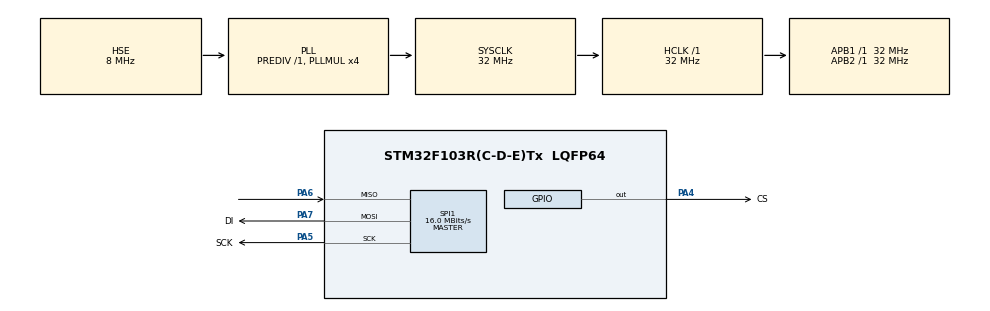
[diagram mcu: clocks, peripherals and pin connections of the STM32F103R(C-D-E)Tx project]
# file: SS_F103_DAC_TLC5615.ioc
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Mcu.Family=STM32F1
Mcu.Name=STM32F103R(C-D-E)Tx
Mcu.Package=LQFP64
NVIC.PriorityGroup=NVIC_PRIORITYGROUP_4
PA4.GPIO_Label=CS
PA4.GPIO_PuPd=GPIO_PULLUP
PA4.Signal=GPIO_Output
PA5.GPIO_Label=SCK
PA5.Mode=Full_Duplex_Master
PA5.Signal=SPI1_SCK
PA6.Mode=Full_Duplex_Master
PA6.Signal=SPI1_MISO
PA7.GPIO_Label=DI
PA7.Mode=Full_Duplex_Master
PA7.Signal=SPI1_MOSI
PD0-OSC_IN.Mode=HSE-External-Oscillator
PD0-OSC_IN.Signal=RCC_OSC_IN
PD1-OSC_OUT.Mode=HSE-External-Oscillator
PD1-OSC_OUT.Signal=RCC_OSC_OUT
ProjectManager.HeapSize=0x200
ProjectManager.StackSize=0x400
ProjectManager.TargetToolchain=MDK-ARM V5.27
RCC.AHBFreq_Value=32000000
RCC.APB1Freq_Value=32000000
RCC.APB1TimFreq_Value=32000000
RCC.APB2Freq_Value=32000000
RCC.APB2TimFreq_Value=32000000
RCC.HCLKFreq_Value=32000000
RCC.PLLMUL=RCC_PLL_MUL4
RCC.PLLSourceVirtual=RCC_PLLSOURCE_HSE
RCC.SYSCLKFreq_VALUE=32000000
RCC.SYSCLKSource=RCC_SYSCLKSOURCE_PLLCLK
RCC.USBFreq_Value=32000000
SPI1.BaudRatePrescaler=SPI_BAUDRATEPRESCALER_2
SPI1.CalculateBaudRate=16.0 MBits/s
SPI1.DataSize=SPI_DATASIZE_8BIT
SPI1.Direction=SPI_DIRECTION_2LINES
SPI1.Mode=SPI_MODE_MASTER
SPI1.VirtualType=VM_MASTER
VP_SYS_VS_ND.Mode=No_Debug
board=custom

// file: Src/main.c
/* USER CODE BEGIN Header */
/**
  ******************************************************************************
  * @file           : main.c
  * @brief          : Main program body
  ******************************************************************************
  * @attention
  *
  * <h2><center>&copy; Copyright (c) 2020 STMicroelectronics.
  * All rights reserved.</center></h2>
  *
  * This software component is licensed by ST under BSD 3-Clause license,
  * the "License"; You may not use this file except in compliance with the
  * License. You may obtain a copy of the License at:
  *                        opensource.org/licenses/BSD-3-Clause
  *
  ******************************************************************************
  */
/* USER CODE END Header */

#include "main.h"
#include "spi.h"
#include "gpio.h"

/* USER CODE BEGIN Includes */
#include "DAC_TLC5615.h"
#include "delay.h"
/* USER CODE END Includes */

void SystemClock_Config(void);

/* USER CODE BEGIN 0 */
FlagStatus SPI_I2S_GetFlagStatus(SPI_TypeDef* SPIx, uint16_t SPI_I2S_FLAG)
{
  FlagStatus bitstatus = RESET;
  /* Check the parameters */
  assert_param(IS_SPI_ALL_PERIPH(SPIx));
  assert_param(IS_SPI_I2S_GET_FLAG(SPI_I2S_FLAG));
  /* Check the status of the specified SPI/I2S flag */
  if ((SPIx->SR & SPI_I2S_FLAG) != (uint16_t)RESET)
  {
    /* SPI_I2S_FLAG is set */
    bitstatus = SET;
  }
  else
  {
    /* SPI_I2S_FLAG is reset */
    bitstatus = RESET;
  }
  /* Return the SPI_I2S_FLAG status */
  return  bitstatus;
}
/* USER CODE END 0 */

int main(void)
{

  /* MCU Configuration--------------------------------------------------------*/

  /* Reset of all peripherals, Initializes the Flash interface and the Systick. */
  HAL_Init();

  /* USER CODE BEGIN Init */
//typedef enum {RESET = 0, SET = !RESET} FlagStatus, ITStatus;
  /* USER CODE END Init */

  /* Configure the system clock */
  SystemClock_Config();

  /* USER CODE BEGIN SysInit */
	delay_init(32);
  /* USER CODE END SysInit */

  /* Initialize all configured peripherals */
  MX_GPIO_Init();
  MX_SPI1_Init();

  /* Infinite loop */
  /* USER CODE BEGIN WHILE */
  while (1)
  {
		//sin_wave();
		MF_Write_data_to_TLC5615(1023);
    /* USER CODE END WHILE */

  }
}

void SystemClock_Config(void)
{
  RCC_OscInitTypeDef RCC_OscInitStruct = {0};
  RCC_ClkInitTypeDef RCC_ClkInitStruct = {0};

  /** Initializes the CPU, AHB and APB busses clocks
  */
  RCC_OscInitStruct.OscillatorType = RCC_OSCILLATORTYPE_HSE;
  RCC_OscInitStruct.HSEState = RCC_HSE_ON;
  RCC_OscInitStruct.HSEPredivValue = RCC_HSE_PREDIV_DIV1;
  RCC_OscInitStruct.HSIState = RCC_HSI_ON;
  RCC_OscInitStruct.PLL.PLLState = RCC_PLL_ON;
  RCC_OscInitStruct.PLL.PLLSource = RCC_PLLSOURCE_HSE;
  RCC_OscInitStruct.PLL.PLLMUL = RCC_PLL_MUL4;
  if (HAL_RCC_OscConfig(&RCC_OscInitStruct) != HAL_OK)
  {
    Error_Handler();
  }
  /** Initializes the CPU, AHB and APB busses clocks
  */
  RCC_ClkInitStruct.ClockType = RCC_CLOCKTYPE_HCLK|RCC_CLOCKTYPE_SYSCLK
                              |RCC_CLOCKTYPE_PCLK1|RCC_CLOCKTYPE_PCLK2;
  RCC_ClkInitStruct.SYSCLKSource = RCC_SYSCLKSOURCE_PLLCLK;
  RCC_ClkInitStruct.AHBCLKDivider = RCC_SYSCLK_DIV1;
  RCC_ClkInitStruct.APB1CLKDivider = RCC_HCLK_DIV1;
  RCC_ClkInitStruct.APB2CLKDivider = RCC_HCLK_DIV1;

  if (HAL_RCC_ClockConfig(&RCC_ClkInitStruct, FLASH_LATENCY_1) != HAL_OK)
  {
    Error_Handler();
  }
}

void Error_Handler(void)
{
}

/************************ (C) COPYRIGHT STMicroelectronics *****END OF FILE****/
